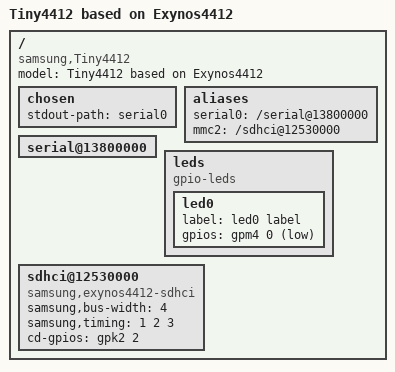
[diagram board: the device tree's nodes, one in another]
/*
 * Odroid-U3/X2 board device tree source
 *
 * Copyright (c) 2014 Samsung Electronics Co., Ltd.
 *		http://www.samsung.com
 *
 * SPDX-License-Identifier:	GPL-2.0+
 */

/dts-v1/;
#include "exynos4412.dtsi"
#include "include/dt-bindings/gpio/gpio.h"

/ {
	model = "Tiny4412 based on Exynos4412";
	compatible = "samsung,Tiny4412", "samsung,exynos4412";
	chosen {
		stdout-path = "serial0";
	};

	aliases {
		serial0 = "/serial@13800000";
		mmc2 = "/sdhci@12530000";
	};
	
	serial@13800000 {
		status = "okay";
	};

	leds {
		compatible = "gpio-leds";
		led0 {
			label = "led0 label";
			gpios = <&gpm4 0 GPIO_ACTIVE_LOW>;
		};
	};
	
	sdhci@12530000 {
		compatible = "samsung,exynos4412-sdhci";
		samsung,bus-width = <4>;
		samsung,timing = <1 2 3>;
		cd-gpios = <&gpk2 2 0>;
	};
};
